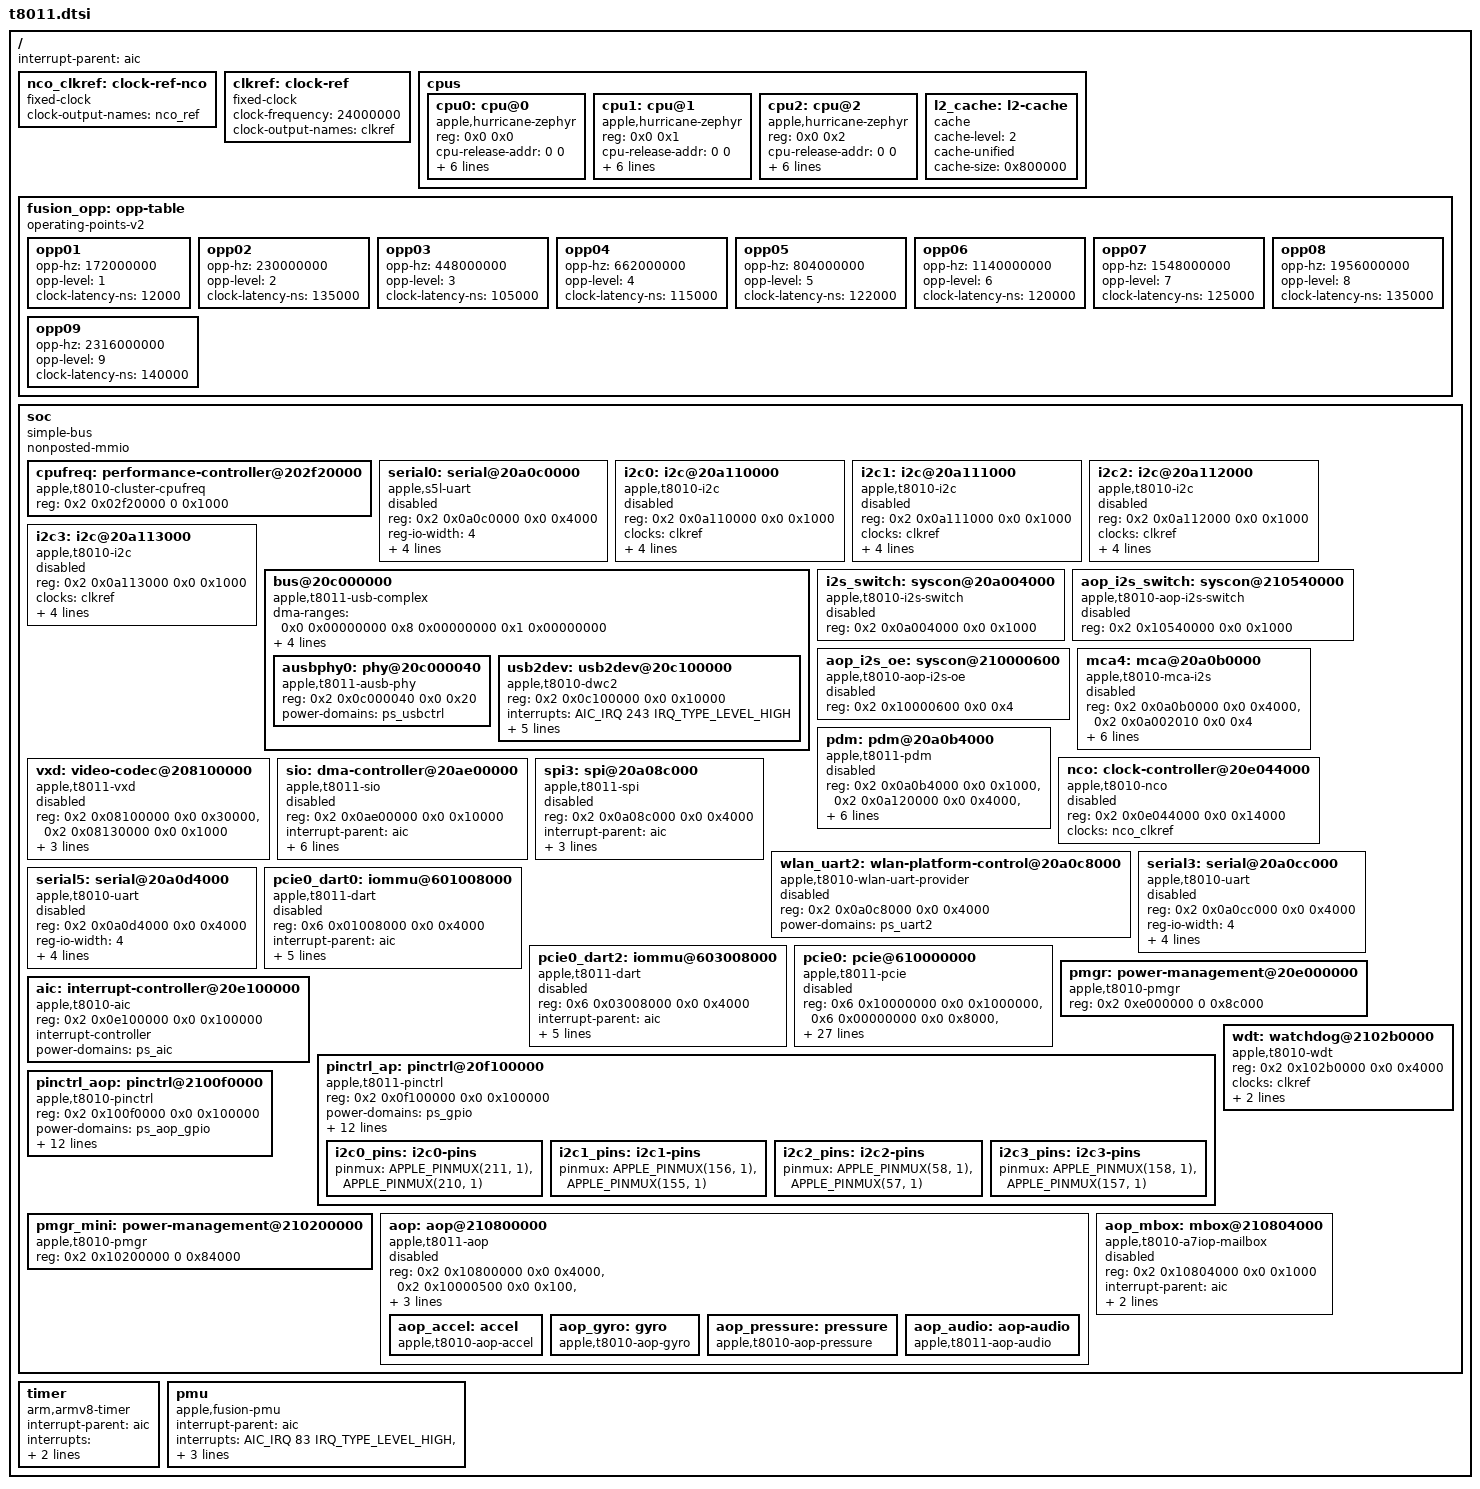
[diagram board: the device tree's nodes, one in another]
// SPDX-License-Identifier: GPL-2.0+ OR MIT
/*
 * Apple T8011 "A10X" SoC
 *
 * Other names: H9G, "Myst"
 *
 * Copyright (c) 2022, Konrad Dybcio <konradybcio@kernel.org>
 */

#include <dt-bindings/gpio/gpio.h>
#include <dt-bindings/interrupt-controller/apple-aic.h>
#include <dt-bindings/interrupt-controller/irq.h>
#include <dt-bindings/phy/phy.h>
#include <dt-bindings/pinctrl/apple.h>

/ {
	interrupt-parent = <&aic>;
	#address-cells = <2>;
	#size-cells = <2>;

	nco_clkref: clock-ref-nco {
		compatible = "fixed-clock";
		#clock-cells = <0>;
		clock-output-names = "nco_ref";
	};

	clkref: clock-ref {
		compatible = "fixed-clock";
		#clock-cells = <0>;
		clock-frequency = <24000000>;
		clock-output-names = "clkref";
	};

	cpus {
		#address-cells = <2>;
		#size-cells = <0>;

		cpu0: cpu@0 {
			compatible = "apple,hurricane-zephyr";
			reg = <0x0 0x0>;
			cpu-release-addr = <0 0>; /* To be filled by loader */
			operating-points-v2 = <&fusion_opp>;
			performance-domains = <&cpufreq>;
			enable-method = "spin-table";
			device_type = "cpu";
			next-level-cache = <&l2_cache>;
			i-cache-size = <0x10000>; /* P-core */
			d-cache-size = <0x10000>; /* P-core */
		};

		cpu1: cpu@1 {
			compatible = "apple,hurricane-zephyr";
			reg = <0x0 0x1>;
			cpu-release-addr = <0 0>; /* To be filled by loader */
			operating-points-v2 = <&fusion_opp>;
			performance-domains = <&cpufreq>;
			enable-method = "spin-table";
			device_type = "cpu";
			next-level-cache = <&l2_cache>;
			i-cache-size = <0x10000>; /* P-core */
			d-cache-size = <0x10000>; /* P-core */
		};

		cpu2: cpu@2 {
			compatible = "apple,hurricane-zephyr";
			reg = <0x0 0x2>;
			cpu-release-addr = <0 0>; /* To be filled by loader */
			operating-points-v2 = <&fusion_opp>;
			performance-domains = <&cpufreq>;
			enable-method = "spin-table";
			device_type = "cpu";
			next-level-cache = <&l2_cache>;
			i-cache-size = <0x10000>; /* P-core */
			d-cache-size = <0x10000>; /* P-core */
		};

		l2_cache: l2-cache {
			compatible = "cache";
			cache-level = <2>;
			cache-unified;
			cache-size = <0x800000>; /* P-cluster */
		};
	};

	fusion_opp: opp-table {
		compatible = "operating-points-v2";

		/*
		 * Apple Fusion Architecture: Hardwired big.LITTLE switcher
		 * that use p-state transitions to switch between cores.
		 *
		 * The E-core frequencies are adjusted so performance scales
		 * linearly with reported clock speed.
		 */

		opp01 {
			opp-hz = /bits/ 64 <172000000>; /* 300 MHz, E-core */
			opp-level = <1>;
			clock-latency-ns = <12000>;
		};
		opp02 {
			opp-hz = /bits/ 64 <230000000>; /* 396 MHz, E-core */
			opp-level = <2>;
			clock-latency-ns = <135000>;
		};
		opp03 {
			opp-hz = /bits/ 64 <448000000>; /* 768 MHz, E-core */
			opp-level = <3>;
			clock-latency-ns = <105000>;
		};
		opp04 {
			opp-hz = /bits/ 64 <662000000>; /* 1152 MHz, E-core */
			opp-level = <4>;
			clock-latency-ns = <115000>;
		};
		opp05 {
			opp-hz = /bits/ 64 <804000000>;
			opp-level = <5>;
			clock-latency-ns = <122000>;
		};
		opp06 {
			opp-hz = /bits/ 64 <1140000000>;
			opp-level = <6>;
			clock-latency-ns = <120000>;
		};
		opp07 {
			opp-hz = /bits/ 64 <1548000000>;
			opp-level = <7>;
			clock-latency-ns = <125000>;
		};
		opp08 {
			opp-hz = /bits/ 64 <1956000000>;
			opp-level = <8>;
			clock-latency-ns = <135000>;
		};
		opp09 {
			opp-hz = /bits/ 64 <2316000000>;
			opp-level = <9>;
			clock-latency-ns = <140000>;
		};
#if 0
		/* Not available until CPU deep sleep is implemented */
		opp10 {
			opp-hz = /bits/ 64 <2400000000>;
			opp-level = <10>;
			clock-latency-ns = <140000>;
			turbo-mode;
		};
#endif
	};

	soc {
		compatible = "simple-bus";
		#address-cells = <2>;
		#size-cells = <2>;
		nonposted-mmio;
		ranges;

		cpufreq: performance-controller@202f20000 {
			compatible = "apple,t8010-cluster-cpufreq", "apple,t8103-cluster-cpufreq", "apple,cluster-cpufreq";
			reg = <0x2 0x02f20000 0 0x1000>;
			#performance-domain-cells = <0>;
		};

		serial0: serial@20a0c0000 {
			compatible = "apple,s5l-uart";
			reg = <0x2 0x0a0c0000 0x0 0x4000>;
			reg-io-width = <4>;
			interrupt-parent = <&aic>;
			interrupts = <AIC_IRQ 216 IRQ_TYPE_LEVEL_HIGH>;
			/* Use the bootloader-enabled clocks for now. */
			clocks = <&clkref>, <&clkref>;
			clock-names = "uart", "clk_uart_baud0";
			power-domains = <&ps_uart0>;
			status = "disabled";
		};

		i2c0: i2c@20a110000 {
			compatible = "apple,t8010-i2c", "apple,i2c";
			reg = <0x2 0x0a110000 0x0 0x1000>;
			clocks = <&clkref>;
			interrupt-parent = <&aic>;
			interrupts = <AIC_IRQ 230 IRQ_TYPE_LEVEL_HIGH>;
			pinctrl-0 = <&i2c0_pins>;
			pinctrl-names = "default";
			power-domains = <&ps_i2c0>;
			#address-cells = <1>;
			#size-cells = <0>;
			status = "disabled";
		};

		i2c1: i2c@20a111000 {
			compatible = "apple,t8010-i2c", "apple,i2c";
			reg = <0x2 0x0a111000 0x0 0x1000>;
			clocks = <&clkref>;
			interrupt-parent = <&aic>;
			interrupts = <AIC_IRQ 231 IRQ_TYPE_LEVEL_HIGH>;
			pinctrl-0 = <&i2c1_pins>;
			pinctrl-names = "default";
			power-domains = <&ps_i2c1>;
			#address-cells = <1>;
			#size-cells = <0>;
			status = "disabled";
		};

		i2c2: i2c@20a112000 {
			compatible = "apple,t8010-i2c", "apple,i2c";
			reg = <0x2 0x0a112000 0x0 0x1000>;
			clocks = <&clkref>;
			interrupt-parent = <&aic>;
			interrupts = <AIC_IRQ 232 IRQ_TYPE_LEVEL_HIGH>;
			pinctrl-0 = <&i2c2_pins>;
			pinctrl-names = "default";
			power-domains = <&ps_i2c2>;
			#address-cells = <1>;
			#size-cells = <0>;
			status = "disabled";
		};

		i2c3: i2c@20a113000 {
			compatible = "apple,t8010-i2c", "apple,i2c";
			reg = <0x2 0x0a113000 0x0 0x1000>;
			clocks = <&clkref>;
			interrupt-parent = <&aic>;
			interrupts = <AIC_IRQ 233 IRQ_TYPE_LEVEL_HIGH>;
			pinctrl-0 = <&i2c3_pins>;
			pinctrl-names = "default";
			power-domains = <&ps_i2c3>;
			#address-cells = <1>;
			#size-cells = <0>;
			status = "disabled";
		};

		bus@20c000000 {
			compatible = "apple,t8011-usb-complex", "simple-pm-bus";
			#address-cells = <2>;
			#size-cells = <2>;
			dma-ranges = <0x0 0x00000000 0x8 0x00000000 0x1 0x00000000>;
			nonposted-mmio;
			ranges;

			reg = <0x2 0x0c000000 0x0 0x40>,
			      <0x2 0x0c000060 0x0 0x40>;
			power-domains = <&ps_usb>;

			ausbphy0: phy@20c000040 {
				compatible = "apple,t8011-ausb-phy", "apple,ausb-phy";
				reg = <0x2 0x0c000040 0x0 0x20>;
				power-domains = <&ps_usbctrl>;
				#phy-cells = <1>;
				/* Tunables to be filled by loader */
			};

			usb2dev: usb2dev@20c100000 {
				compatible = "apple,t8010-dwc2", "apple,dwc2";
				reg = <0x2 0x0c100000 0x0 0x10000>;
				interrupts = <AIC_IRQ 243 IRQ_TYPE_LEVEL_HIGH>;
				clocks = <&clkref>;
				clock-names = "otg";
				phys = <&ausbphy0 PHY_TYPE_USB2>;
				phy-names = "usb2-phy";
				power-domains = <&ps_usb2dev>;
				resets = <&ps_usb2dev>;
				dr_mode = "peripheral";
			};
#if 0
			ehci0: usb-ehci@20c200000 {
				compatible = "apple,t8010-ehci", "generic-ehci";
				reg = <0x2 0x0c200000 0x0 0x10000>;
				interrupts = <AIC_IRQ 244 IRQ_TYPE_LEVEL_HIGH>;
				power-domains = <&ps_usb2host>;
			};

			xhci0: usb-xhci@20c400000 {
				compatible = "apple,t8011-xhci", "generic-xhci";
				reg = <0x2 0x0c400000 0x0 0x10000>;
				interrupts = <AIC_IRQ 262 IRQ_TYPE_LEVEL_HIGH>;
				power-domains = <&ps_usb3host>;
				/* FIXME: Time out on setup (need firmware?) */
				status = "disabled";
			};
#endif
		};

		i2s_switch: syscon@20a004000 {
			compatible = "apple,t8010-i2s-switch", "syscon";
			reg = <0x2 0x0a004000 0x0 0x1000>;
			status = "disabled";
		};

		aop_i2s_switch: syscon@210540000 {
			compatible = "apple,t8010-aop-i2s-switch", "syscon";
			reg = <0x2 0x10540000 0x0 0x1000>;
			status = "disabled";
		};

		aop_i2s_oe: syscon@210000600 {
			compatible = "apple,t8010-aop-i2s-oe", "syscon";
			reg = <0x2 0x10000600 0x0 0x4>;
			status = "disabled";
		};

		mca4: mca@20a0b0000 {
			compatible = "apple,t8010-mca-i2s";
			reg = <0x2 0x0a0b0000 0x0 0x4000>,
			      <0x2 0x0a002010 0x0 0x4>;
			reg-names = "mca", "mclk";
			interrupt-parent = <&aic>;
			interrupts = <AIC_IRQ 229 IRQ_TYPE_LEVEL_HIGH>;
			power-domains = <&ps_mca4>;
			clocks = <&nco 4>;
			clock-names = "bitclk";
			dmas = <&sio 0x30>;
			dma-names = "tx";
			#clock-cells = <0>;
			clock-output-names = "mca4-mclk";
			#sound-dai-cells = <0>;
			status = "disabled";
		};

		pdm: pdm@20a0b4000 {
			compatible = "apple,t8011-pdm";
			reg = <0x2 0x0a0b4000 0x0 0x1000>,
			      <0x2 0x0a120000 0x0 0x4000>,
			      <0x2 0x0a124000 0x0 0x4000>;
			reg-names = "pdm", "dec0", "dec1";
			interrupt-parent = <&aic>;
			interrupts = <AIC_IRQ 236 IRQ_TYPE_LEVEL_HIGH>;
			clocks = <&aop_audio>;
			power-domains = <&ps_hfd0>;
			dmas = <&sio 0x5b>;
			dma-names = "rx";
			#sound-dai-cells = <0>;
			status = "disabled";
		};

		nco: clock-controller@20e044000 {
			compatible = "apple,t8010-nco";
			reg = <0x2 0x0e044000 0x0 0x14000>;
			clocks = <&nco_clkref>;
			#clock-cells = <1>;
			status = "disabled";
		};

		/*
		 * Imagination MSVDX ("VXD") H.264 decoder, as on the T8010; it
		 * has its own two-level GART, so no DART.
		 */
		vxd: video-codec@208100000 {
			compatible = "apple,t8011-vxd", "apple,t8010-vxd";
			reg = <0x2 0x08100000 0x0 0x30000>,
			      <0x2 0x08130000 0x0 0x1000>;
			interrupt-parent = <&aic>;
			interrupts = <AIC_IRQ 169 IRQ_TYPE_LEVEL_HIGH>;
			power-domains = <&ps_vdec0>;
			status = "disabled";
		};

		sio: dma-controller@20ae00000 {
			compatible = "apple,t8011-sio";
			reg = <0x2 0x0ae00000 0x0 0x10000>;
			reg-names = "a7iop";
			interrupt-parent = <&aic>;
			interrupts = <AIC_IRQ 209 IRQ_TYPE_LEVEL_HIGH>,
				     <AIC_IRQ 208 IRQ_TYPE_LEVEL_HIGH>,
				     <AIC_IRQ 211 IRQ_TYPE_LEVEL_HIGH>,
				     <AIC_IRQ 210 IRQ_TYPE_LEVEL_HIGH>;
			power-domains = <&ps_sio>;
			firmware-name = "apple/t8011-smartio.bin";
			#dma-cells = <1>;
			status = "disabled";
		};

		spi3: spi@20a08c000 {
			compatible = "apple,t8011-spi", "apple,t8010-spi", "apple,spi";
			reg = <0x2 0x0a08c000 0x0 0x4000>;
			interrupt-parent = <&aic>;
			interrupts = <AIC_IRQ 215 IRQ_TYPE_LEVEL_HIGH>;
			clocks = <&clkref>;
			power-domains = <&ps_spi3>;
			#address-cells = <1>;
			#size-cells = <0>;
			status = "disabled";
		};

		wlan_uart2: wlan-platform-control@20a0c8000 {
			compatible = "apple,t8010-wlan-uart-provider";
			reg = <0x2 0x0a0c8000 0x0 0x4000>;
			power-domains = <&ps_uart2>;
			status = "disabled";
		};

		serial3: serial@20a0cc000 {
			compatible = "apple,t8010-uart", "apple,s5l-uart";
			reg = <0x2 0x0a0cc000 0x0 0x4000>;
			reg-io-width = <4>;
			interrupt-parent = <&aic>;
			interrupts = <AIC_IRQ 219 IRQ_TYPE_LEVEL_HIGH>;
			/* Use the bootloader-enabled clocks for now. */
			clocks = <&clkref>, <&clkref>;
			clock-names = "uart", "clk_uart_baud0";
			power-domains = <&ps_uart3>;
			status = "disabled";
		};

		serial5: serial@20a0d4000 {
			compatible = "apple,t8010-uart", "apple,s5l-uart";
			reg = <0x2 0x0a0d4000 0x0 0x4000>;
			reg-io-width = <4>;
			interrupt-parent = <&aic>;
			interrupts = <AIC_IRQ 221 IRQ_TYPE_LEVEL_HIGH>;
			/* Use the bootloader-enabled clocks for now. */
			clocks = <&clkref>, <&clkref>;
			clock-names = "uart", "clk_uart_baud0";
			power-domains = <&ps_uart5>;
			status = "disabled";
		};

		pcie0_dart0: iommu@601008000 {
			compatible = "apple,t8011-dart", "apple,s5l8960x-dart";
			reg = <0x6 0x01008000 0x0 0x4000>;
			interrupt-parent = <&aic>;
			interrupts = <AIC_IRQ 271 IRQ_TYPE_LEVEL_HIGH>;
			power-domains = <&ps_pcie>;
			#iommu-cells = <5>;
			apple,error-reflector = /bits/ 64 <0x20fffc000>;
			apple,fetch-config = <0x000e0303>;
			apple,diag-config = <0x00000100>;
			status = "disabled";
		};

		pcie0_dart2: iommu@603008000 {
			compatible = "apple,t8011-dart", "apple,s5l8960x-dart";
			reg = <0x6 0x03008000 0x0 0x4000>;
			interrupt-parent = <&aic>;
			interrupts = <AIC_IRQ 277 IRQ_TYPE_LEVEL_HIGH>;
			power-domains = <&ps_pcie>;
			#iommu-cells = <5>;
			apple,error-reflector = /bits/ 64 <0x20fffc000>;
			apple,fetch-config = <0x000e0303>;
			apple,diag-config = <0x00000100>;
			status = "disabled";
		};

		/* H9P root complex: six root ports, storage on port 0 (NVMMU). */
		pcie0: pcie@610000000 {
			compatible = "apple,t8011-pcie";
			device_type = "pci";
			reg = <0x6 0x10000000 0x0 0x1000000>,
			      <0x6 0x00000000 0x0 0x8000>,
			      <0x6 0x00008000 0x0 0x4000>,
			      <0x6 0x0a000000 0x0 0x40000>,
			      <0x6 0x01000000 0x0 0x4000>,
			      <0x6 0x02000000 0x0 0x4000>,
			      <0x6 0x03000000 0x0 0x4000>,
			      <0x6 0x04000000 0x0 0x4000>,
			      <0x6 0x05000000 0x0 0x4000>,
			      <0x6 0x06000000 0x0 0x4000>,
			      <0x6 0x01004000 0x0 0x4000>;
			reg-names = "config", "rc", "phy", "phy-ip",
				    "port0", "port1", "port2", "port3", "port4", "port5",
				    "nvmmu";

			interrupt-parent = <&aic>;
			interrupts = <AIC_IRQ 270 IRQ_TYPE_LEVEL_HIGH>,
				     <AIC_IRQ 273 IRQ_TYPE_LEVEL_HIGH>,
				     <AIC_IRQ 276 IRQ_TYPE_LEVEL_HIGH>,
				     <AIC_IRQ 279 IRQ_TYPE_LEVEL_HIGH>,
				     <AIC_IRQ 282 IRQ_TYPE_LEVEL_HIGH>,
				     <AIC_IRQ 285 IRQ_TYPE_LEVEL_HIGH>,
				     <AIC_IRQ 272 IRQ_TYPE_EDGE_RISING>;
			interrupt-names = "port0", "port1", "port2", "port3",
					  "port4", "port5", "nvmmu";
			interrupt-controller;
			#interrupt-cells = <1>;

			msi-controller;
			msi-parent = <&pcie0>;
			msi-ranges = <&aic AIC_IRQ 288 IRQ_TYPE_EDGE_RISING 32>;
			apple,msi-doorbell = <0xbffff000>;
			apple,nvmmu-iova = <0xbc000000>;

			#address-cells = <3>;
			#size-cells = <2>;
			bus-range = <0 8>;
			ranges = <0x43000000 0x6 0x20000000 0x6 0x20000000 0x1 0xa0000000>,
				 <0x02000000 0x0 0xc0000000 0x7 0xc0000000 0x0 0x40000000>;

			power-domains = <&ps_pcie>;
			clocks = <&ps_pcie_aux>, <&ps_pcie_ref>;
			clock-names = "aux", "ref";
			status = "disabled";
		};

		pmgr: power-management@20e000000 {
			compatible = "apple,t8010-pmgr", "apple,pmgr", "syscon", "simple-mfd";
			#address-cells = <1>;
			#size-cells = <1>;

			reg = <0x2 0xe000000 0 0x8c000>;
		};

		aic: interrupt-controller@20e100000 {
			compatible = "apple,t8010-aic", "apple,aic";
			reg = <0x2 0x0e100000 0x0 0x100000>;
			#interrupt-cells = <3>;
			interrupt-controller;
			power-domains = <&ps_aic>;
		};

		/* The A9's function encoding (iPad Pro 2 display sync pins). */
		pinctrl_ap: pinctrl@20f100000 {
			compatible = "apple,t8011-pinctrl", "apple,s8000-pinctrl", "apple,pinctrl";
			reg = <0x2 0x0f100000 0x0 0x100000>;
			power-domains = <&ps_gpio>;

			gpio-controller;
			#gpio-cells = <2>;
			gpio-ranges = <&pinctrl_ap 0 0 219>;
			apple,npins = <219>;

			interrupt-controller;
			#interrupt-cells = <2>;
			interrupt-parent = <&aic>;
			interrupts = <AIC_IRQ 42 IRQ_TYPE_LEVEL_HIGH>,
				     <AIC_IRQ 43 IRQ_TYPE_LEVEL_HIGH>,
				     <AIC_IRQ 44 IRQ_TYPE_LEVEL_HIGH>,
				     <AIC_IRQ 45 IRQ_TYPE_LEVEL_HIGH>,
				     <AIC_IRQ 46 IRQ_TYPE_LEVEL_HIGH>,
				     <AIC_IRQ 47 IRQ_TYPE_LEVEL_HIGH>,
				     <AIC_IRQ 48 IRQ_TYPE_LEVEL_HIGH>;

			i2c0_pins: i2c0-pins {
				pinmux = <APPLE_PINMUX(211, 1)>,
					 <APPLE_PINMUX(210, 1)>;
			};

			i2c1_pins: i2c1-pins {
				pinmux = <APPLE_PINMUX(156, 1)>,
					 <APPLE_PINMUX(155, 1)>;
			};

			i2c2_pins: i2c2-pins {
				pinmux = <APPLE_PINMUX(58, 1)>,
					 <APPLE_PINMUX(57, 1)>;
			};

			i2c3_pins: i2c3-pins {
				pinmux = <APPLE_PINMUX(158, 1)>,
					 <APPLE_PINMUX(157, 1)>;
			};
		};

		pinctrl_aop: pinctrl@2100f0000 {
			compatible = "apple,t8010-pinctrl", "apple,pinctrl";
			reg = <0x2 0x100f0000 0x0 0x100000>;
			power-domains = <&ps_aop_gpio>;

			gpio-controller;
			#gpio-cells = <2>;
			gpio-ranges = <&pinctrl_aop 0 0 42>;
			apple,npins = <42>;

			interrupt-controller;
			#interrupt-cells = <2>;
			interrupt-parent = <&aic>;
			interrupts = <AIC_IRQ 125 IRQ_TYPE_LEVEL_HIGH>,
				     <AIC_IRQ 126 IRQ_TYPE_LEVEL_HIGH>,
				     <AIC_IRQ 127 IRQ_TYPE_LEVEL_HIGH>,
				     <AIC_IRQ 128 IRQ_TYPE_LEVEL_HIGH>,
				     <AIC_IRQ 129 IRQ_TYPE_LEVEL_HIGH>,
				     <AIC_IRQ 130 IRQ_TYPE_LEVEL_HIGH>,
				     <AIC_IRQ 131 IRQ_TYPE_LEVEL_HIGH>;
		};

		pmgr_mini: power-management@210200000 {
			compatible = "apple,t8010-pmgr", "apple,pmgr", "syscon", "simple-mfd";
			#address-cells = <1>;
			#size-cells = <1>;

			reg = <0x2 0x10200000 0 0x84000>;
		};

		wdt: watchdog@2102b0000 {
			compatible = "apple,t8010-wdt", "apple,wdt";
			reg = <0x2 0x102b0000 0x0 0x4000>;
			clocks = <&clkref>;
			interrupt-parent = <&aic>;
			interrupts = <AIC_IRQ 4 IRQ_TYPE_LEVEL_HIGH>;
		};

		/*
		 * The ipad7aop firmware runs past the T8010's 0xa0000 of SRAM, up
		 * to the boot loader's reservation at 0x210ed8000.
		 */
		aop: aop@210800000 {
			compatible = "apple,t8011-aop";
			reg = <0x2 0x10800000 0x0 0x4000>,
			      <0x2 0x10000500 0x0 0x100>,
			      <0x2 0x10e00000 0x0 0xd8000>;
			reg-names = "akf", "control", "sram";
			mboxes = <&aop_mbox>;
			mbox-names = "mbox";
			status = "disabled";

			aop_accel: accel {
				compatible = "apple,t8010-aop-accel";
			};

			aop_gyro: gyro {
				compatible = "apple,t8010-aop-gyro";
			};

			aop_pressure: pressure {
				compatible = "apple,t8010-aop-pressure";
			};

			aop_audio: aop-audio {
				compatible = "apple,t8011-aop-audio", "apple,t8010-aop-audio";
				#clock-cells = <0>;
			};
		};

		aop_mbox: mbox@210804000 {
			compatible = "apple,t8010-a7iop-mailbox";
			reg = <0x2 0x10804000 0x0 0x1000>;
			interrupt-parent = <&aic>;
			interrupts = <AIC_IRQ 142 IRQ_TYPE_LEVEL_HIGH>,
				     <AIC_IRQ 145 IRQ_TYPE_LEVEL_HIGH>;
			interrupt-names = "send-empty", "recv-not-empty";
			#mbox-cells = <0>;
			status = "disabled";
		};
	};

	timer {
		compatible = "arm,armv8-timer";
		interrupt-parent = <&aic>;
		interrupt-names = "phys", "virt";
		/* Note that A10X doesn't actually have a hypervisor (EL2 is not implemented). */
		interrupts = <AIC_FIQ AIC_TMR_GUEST_PHYS IRQ_TYPE_LEVEL_HIGH>,
			     <AIC_FIQ AIC_TMR_GUEST_VIRT IRQ_TYPE_LEVEL_HIGH>;
	};

	pmu {
		compatible = "apple,fusion-pmu";
		interrupt-parent = <&aic>;
		interrupts = <AIC_IRQ 83 IRQ_TYPE_LEVEL_HIGH>,
			     <AIC_IRQ 86 IRQ_TYPE_LEVEL_HIGH>,
			     <AIC_IRQ 89 IRQ_TYPE_LEVEL_HIGH>;
		interrupt-affinity = <&cpu0 &cpu1 &cpu2>;
	};
};

#include "t8011-pmgr.dtsi"
